# ESP32S31_RADIO register map
Vendor: Espressif; Series: ESP32-S31; File version: 3.52
Registers are 32-bit, read-write, no defined reset value unless marked. A register's access mark holds for its fields unless they carry their own. Offsets are from the block's base; [hi:lo] are bit positions; {n}, {i} and the like mark numbered series; 'fields as' and 'values as' point back to an identical list.

## MODEM_RADIO_CORE_LOW_OBSERVED — Sparse source-qualified word views in the existing owned MMIO aperture; individual meanings and side effects remain unknown.
Base 0x20100000
0x470 WORD_0470_OPAQUE ro — Opaque: meaning not established. Aligned 32-bit bus view explicitly addressed by the cited vendor source. No reset or hardware write effect is established.
  [31:0] BITS_0_31_OPAQUE — Opaque: meaning not established. Observed source use; the individual hardware meaning is unknown.
0x474 WORD_0474_OPAQUE ro — Opaque: meaning not established. Aligned 32-bit bus view explicitly addressed by the cited vendor source. No reset or hardware write effect is established.
  fields as WORD_0470_OPAQUE
0x1018 WORD_1018_OPAQUE ro — Opaque: meaning not established. Aligned 32-bit bus view explicitly addressed by the cited vendor source. No reset or hardware write effect is established.
  [0] BIT_0_OPAQUE — Opaque: meaning not established. Observed source use; the individual hardware meaning is unknown.
0x1038 WORD_1038_OPAQUE ro — Opaque: meaning not established. Aligned 32-bit bus view explicitly addressed by the cited vendor source. No reset or hardware write effect is established.
  fields as WORD_1018_OPAQUE
0x1048 WORD_1048_OPAQUE ro — Opaque: meaning not established. Aligned 32-bit bus view explicitly addressed by the cited vendor source. No reset or hardware write effect is established.
  fields as WORD_1018_OPAQUE
0x106C WORD_106C_OPAQUE — Opaque: meaning not established. Aligned 32-bit bus view explicitly addressed by the cited vendor source. No reset or hardware write effect is established.
  fields as WORD_0470_OPAQUE
0x1088 WORD_1088_OPAQUE — Opaque: meaning not established. Aligned 32-bit bus view explicitly addressed by the cited vendor source. No reset or hardware write effect is established.
  [7:0] BITS_0_7_OPAQUE — Opaque: meaning not established. Observed source use; the individual hardware meaning is unknown.
0x10D0 WORD_10D0_OPAQUE ro — Opaque: meaning not established. Aligned 32-bit bus view explicitly addressed by the cited vendor source. No reset or hardware write effect is established.
  [20:0] BITS_0_20_OPAQUE — Opaque: meaning not established. Observed source use; the individual hardware meaning is unknown.
0x10D4 WORD_10D4_OPAQUE ro — Opaque: meaning not established. Aligned 32-bit bus view explicitly addressed by the cited vendor source. No reset or hardware write effect is established.
  fields as WORD_10D0_OPAQUE
0x122C WORD_122C_OPAQUE ro — Opaque: meaning not established. Aligned 32-bit bus view explicitly addressed by the cited vendor source. No reset or hardware write effect is established.
  fields as WORD_0470_OPAQUE
0x1230 WORD_1230_OPAQUE ro — Opaque: meaning not established. Aligned 32-bit bus view explicitly addressed by the cited vendor source. No reset or hardware write effect is established.
  [19:0] BITS_0_19_OPAQUE — Opaque: meaning not established. Observed source use; the individual hardware meaning is unknown.
0x126C WORD_126C_OPAQUE ro — Opaque: meaning not established. Aligned 32-bit bus view explicitly addressed by the cited vendor source. No reset or hardware write effect is established.
  fields as WORD_0470_OPAQUE
0x1270 WORD_1270_OPAQUE ro — Opaque: meaning not established. Aligned 32-bit bus view explicitly addressed by the cited vendor source. No reset or hardware write effect is established.
  fields as WORD_0470_OPAQUE
0x1274 WORD_1274_OPAQUE ro — Opaque: meaning not established. Aligned 32-bit bus view explicitly addressed by the cited vendor source. No reset or hardware write effect is established.
  fields as WORD_0470_OPAQUE
0x1278 WORD_1278_OPAQUE ro — Opaque: meaning not established. Aligned 32-bit bus view explicitly addressed by the cited vendor source. No reset or hardware write effect is established.
  fields as WORD_0470_OPAQUE
0x1298 WORD_1298_OPAQUE ro — Opaque: meaning not established. Aligned 32-bit bus view explicitly addressed by the cited vendor source. No reset or hardware write effect is established.
  fields as WORD_0470_OPAQUE
0x12AC WORD_12AC_OPAQUE ro — Opaque: meaning not established. Aligned 32-bit bus view explicitly addressed by the cited vendor source. No reset or hardware write effect is established.
  fields as WORD_0470_OPAQUE
0x12B0 WORD_12B0_OPAQUE ro — Opaque: meaning not established. Aligned 32-bit bus view explicitly addressed by the cited vendor source. No reset or hardware write effect is established.
  fields as WORD_0470_OPAQUE
0x12B4 WORD_12B4_OPAQUE ro — Opaque: meaning not established. Aligned 32-bit bus view explicitly addressed by the cited vendor source. No reset or hardware write effect is established.
  fields as WORD_0470_OPAQUE
0x12B8 WORD_12B8_OPAQUE ro — Opaque: meaning not established. Aligned 32-bit bus view explicitly addressed by the cited vendor source. No reset or hardware write effect is established.
  fields as WORD_0470_OPAQUE
0x12BC WORD_12BC_OPAQUE ro — Opaque: meaning not established. Aligned 32-bit bus view explicitly addressed by the cited vendor source. No reset or hardware write effect is established.
  fields as WORD_0470_OPAQUE
0x12C0 WORD_12C0_OPAQUE ro — Opaque: meaning not established. Aligned 32-bit bus view explicitly addressed by the cited vendor source. No reset or hardware write effect is established.
  fields as WORD_0470_OPAQUE
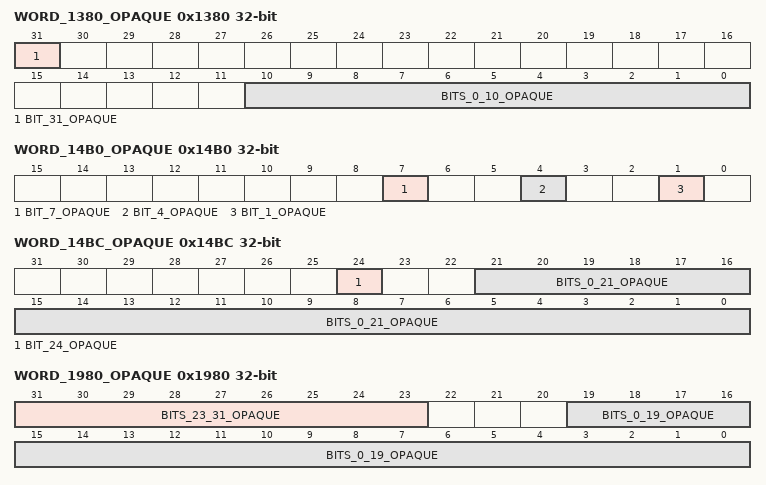
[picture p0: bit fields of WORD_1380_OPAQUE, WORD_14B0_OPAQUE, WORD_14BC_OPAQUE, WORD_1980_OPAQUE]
0x1380 WORD_1380_OPAQUE — Opaque: meaning not established. Aligned 32-bit bus view explicitly addressed by the cited vendor source. No reset or hardware write effect is established.
  [31] BIT_31_OPAQUE — Opaque: meaning not established. Observed source use; the individual hardware meaning is unknown.
  [10:0] BITS_0_10_OPAQUE — Opaque: meaning not established. Observed source use; the individual hardware meaning is unknown.
0x13D8 WORD_13D8_OPAQUE — Opaque: meaning not established. Aligned 32-bit bus view explicitly addressed by the cited vendor source. No reset or hardware write effect is established.
  fields as WORD_0470_OPAQUE
0x13DC WORD_13DC_OPAQUE — Opaque: meaning not established. Aligned 32-bit bus view explicitly addressed by the cited vendor source. No reset or hardware write effect is established.
  fields as WORD_0470_OPAQUE
0x13E0 WORD_13E0_OPAQUE — Opaque: meaning not established. Aligned 32-bit bus view explicitly addressed by the cited vendor source. No reset or hardware write effect is established.
  fields as WORD_0470_OPAQUE
0x13E4 WORD_13E4_OPAQUE — Opaque: meaning not established. Aligned 32-bit bus view explicitly addressed by the cited vendor source. No reset or hardware write effect is established.
  fields as WORD_0470_OPAQUE
0x13F4 WORD_13F4_OPAQUE — Opaque: meaning not established. Aligned 32-bit bus view explicitly addressed by the cited vendor source. No reset or hardware write effect is established.
  [1] BIT_1_OPAQUE — Opaque: meaning not established. Observed source use; the individual hardware meaning is unknown.
0x13FC WORD_13FC_OPAQUE — Opaque: meaning not established. Aligned 32-bit bus view explicitly addressed by the cited vendor source. No reset or hardware write effect is established.
  [27:0] BITS_0_27_OPAQUE — Opaque: meaning not established. Observed source use; the individual hardware meaning is unknown.
0x1430 WORD_1430_OPAQUE — Opaque: meaning not established. Aligned 32-bit bus view explicitly addressed by the cited vendor source. No reset or hardware write effect is established.
  fields as WORD_0470_OPAQUE
0x1434 WORD_1434_OPAQUE — Opaque: meaning not established. Aligned 32-bit bus view explicitly addressed by the cited vendor source. No reset or hardware write effect is established.
  fields as WORD_0470_OPAQUE
0x1438 WORD_1438_OPAQUE — Opaque: meaning not established. Aligned 32-bit bus view explicitly addressed by the cited vendor source. No reset or hardware write effect is established.
  fields as WORD_0470_OPAQUE
0x143C WORD_143C_OPAQUE — Opaque: meaning not established. Aligned 32-bit bus view explicitly addressed by the cited vendor source. No reset or hardware write effect is established.
  fields as WORD_0470_OPAQUE
0x1450 WORD_1450_OPAQUE — Opaque: meaning not established. Aligned 32-bit bus view explicitly addressed by the cited vendor source. No reset or hardware write effect is established.
  fields as WORD_0470_OPAQUE
0x145C WORD_145C_OPAQUE — Opaque: meaning not established. Aligned 32-bit bus view explicitly addressed by the cited vendor source. No reset or hardware write effect is established.
  fields as WORD_0470_OPAQUE
0x1470 WORD_1470_OPAQUE — Opaque: meaning not established. Aligned 32-bit bus view explicitly addressed by the cited vendor source. No reset or hardware write effect is established.
  fields as WORD_0470_OPAQUE
0x147C WORD_147C_OPAQUE ro — Opaque: meaning not established. Aligned 32-bit bus view explicitly addressed by the cited vendor source. No reset or hardware write effect is established.
  fields as WORD_1018_OPAQUE
0x14B0 WORD_14B0_OPAQUE — Opaque: meaning not established. Aligned 32-bit bus view explicitly addressed by the cited vendor source. No reset or hardware write effect is established.
  [7] BIT_7_OPAQUE — Opaque: meaning not established. Observed source use; the individual hardware meaning is unknown.
  [4] BIT_4_OPAQUE — Opaque: meaning not established. Observed source use; the individual hardware meaning is unknown.
  [1] BIT_1_OPAQUE — Opaque: meaning not established. Observed source use; the individual hardware meaning is unknown.
0x14BC WORD_14BC_OPAQUE ro — Opaque: meaning not established. Aligned 32-bit bus view explicitly addressed by the cited vendor source. No reset or hardware write effect is established.
  [24] BIT_24_OPAQUE — Opaque: meaning not established. Observed source use; the individual hardware meaning is unknown.
  [21:0] BITS_0_21_OPAQUE — Opaque: meaning not established. Observed source use; the individual hardware meaning is unknown.
0x14C4 WORD_14C4_OPAQUE — Opaque: meaning not established. Aligned 32-bit bus view explicitly addressed by the cited vendor source. No reset or hardware write effect is established.
  [10] BIT_10_OPAQUE — Opaque: meaning not established. Observed source use; the individual hardware meaning is unknown.
0x14C8 WORD_14C8_OPAQUE — Opaque: meaning not established. Aligned 32-bit bus view explicitly addressed by the cited vendor source. No reset or hardware write effect is established.
  fields as WORD_14C4_OPAQUE
0x14CC WORD_14CC_OPAQUE ro — Opaque: meaning not established. Aligned 32-bit bus view explicitly addressed by the cited vendor source. No reset or hardware write effect is established.
  [10:9] BITS_9_10_OPAQUE — Opaque: meaning not established. Observed source use; the individual hardware meaning is unknown.
0x1508 WORD_1508_OPAQUE — Opaque: meaning not established. Aligned 32-bit bus view explicitly addressed by the cited vendor source. No reset or hardware write effect is established.
  [6:0] BITS_0_6_OPAQUE — Opaque: meaning not established. Observed source use; the individual hardware meaning is unknown.
0x1510 WORD_1510_OPAQUE — Opaque: meaning not established. Aligned 32-bit bus view explicitly addressed by the cited vendor source. No reset or hardware write effect is established.
  fields as WORD_0470_OPAQUE
0x1514 WORD_1514_OPAQUE — Opaque: meaning not established. Aligned 32-bit bus view explicitly addressed by the cited vendor source. No reset or hardware write effect is established.
  fields as WORD_0470_OPAQUE
0x1518 WORD_1518_OPAQUE — Opaque: meaning not established. Aligned 32-bit bus view explicitly addressed by the cited vendor source. No reset or hardware write effect is established.
  fields as WORD_0470_OPAQUE
0x1524 WORD_1524_OPAQUE — Opaque: meaning not established. Aligned 32-bit bus view explicitly addressed by the cited vendor source. No reset or hardware write effect is established.
  fields as WORD_0470_OPAQUE
0x1528 WORD_1528_OPAQUE — Opaque: meaning not established. Aligned 32-bit bus view explicitly addressed by the cited vendor source. No reset or hardware write effect is established.
  fields as WORD_0470_OPAQUE
0x1548 WORD_1548_OPAQUE ro — Opaque: meaning not established. Aligned 32-bit bus view explicitly addressed by the cited vendor source. No reset or hardware write effect is established.
  fields as WORD_1088_OPAQUE
0x1980 WORD_1980_OPAQUE — Opaque: meaning not established. Aligned 32-bit bus view explicitly addressed by the cited vendor source. No reset or hardware write effect is established.
  [31:23] BITS_23_31_OPAQUE — Opaque: meaning not established. Observed source use; the individual hardware meaning is unknown.
  [19:0] BITS_0_19_OPAQUE — Opaque: meaning not established. Observed source use; the individual hardware meaning is unknown.
0x198C WORD_198C_OPAQUE — Opaque: meaning not established. Aligned 32-bit bus view explicitly addressed by the cited vendor source. No reset or hardware write effect is established.
  fields as WORD_0470_OPAQUE
0x1994 WORD_1994_OPAQUE — Opaque: meaning not established. Aligned 32-bit bus view explicitly addressed by the cited vendor source. No reset or hardware write effect is established.
  fields as WORD_0470_OPAQUE
0x1FFC WORD_1FFC_OPAQUE — Opaque: meaning not established. Aligned 32-bit bus view explicitly addressed by the cited vendor source. No reset or hardware write effect is established.
  fields as WORD_0470_OPAQUE
0x2018 WORD_2018_OPAQUE — Opaque: meaning not established. Aligned 32-bit bus view explicitly addressed by the cited vendor source. No reset or hardware write effect is established.
  [26:16] BITS_16_26_OPAQUE — Opaque: meaning not established. Observed source use; the individual hardware meaning is unknown.
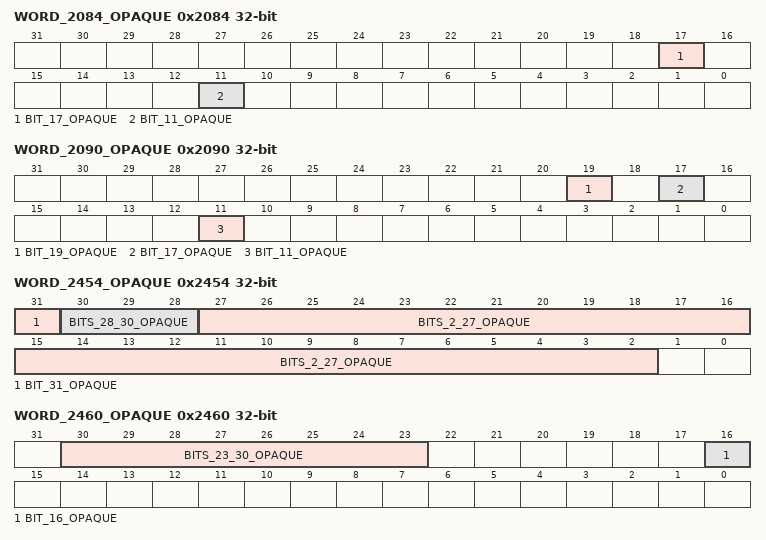
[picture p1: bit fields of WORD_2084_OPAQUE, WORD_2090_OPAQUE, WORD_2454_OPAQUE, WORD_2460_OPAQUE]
0x2084 WORD_2084_OPAQUE — Opaque: meaning not established. Aligned 32-bit bus view explicitly addressed by the cited vendor source. No reset or hardware write effect is established.
  [17] BIT_17_OPAQUE — Opaque: meaning not established. Observed source use; the individual hardware meaning is unknown.
  [11] BIT_11_OPAQUE — Opaque: meaning not established. Observed source use; the individual hardware meaning is unknown.
0x2088 WORD_2088_OPAQUE ro — Opaque: meaning not established. Aligned 32-bit bus view explicitly addressed by the cited vendor source. No reset or hardware write effect is established.
  fields as WORD_1230_OPAQUE
0x2090 WORD_2090_OPAQUE — Opaque: meaning not established. Aligned 32-bit bus view explicitly addressed by the cited vendor source. No reset or hardware write effect is established.
  [19] BIT_19_OPAQUE — Opaque: meaning not established. Observed source use; the individual hardware meaning is unknown.
  [17] BIT_17_OPAQUE — Opaque: meaning not established. Observed source use; the individual hardware meaning is unknown.
  [11] BIT_11_OPAQUE — Opaque: meaning not established. Observed source use; the individual hardware meaning is unknown.
0x20AC WORD_20AC_OPAQUE — Opaque: meaning not established. Aligned 32-bit bus view explicitly addressed by the cited vendor source. No reset or hardware write effect is established.
  [31:29] BITS_29_31_OPAQUE — Opaque: meaning not established. Observed source use; the individual hardware meaning is unknown.
0x21B0 WORD_21B0_OPAQUE — Opaque: meaning not established. Aligned 32-bit bus view explicitly addressed by the cited vendor source. No reset or hardware write effect is established.
  fields as WORD_0470_OPAQUE
0x2454 WORD_2454_OPAQUE — Opaque: meaning not established. Aligned 32-bit bus view explicitly addressed by the cited vendor source. No reset or hardware write effect is established.
  [31] BIT_31_OPAQUE — Opaque: meaning not established. Observed source use; the individual hardware meaning is unknown.
  [30:28] BITS_28_30_OPAQUE — Opaque: meaning not established. Observed source use; the individual hardware meaning is unknown.
  [27:2] BITS_2_27_OPAQUE — Opaque: meaning not established. Observed source use; the individual hardware meaning is unknown.
0x2458 WORD_2458_OPAQUE — Opaque: meaning not established. Aligned 32-bit bus view explicitly addressed by the cited vendor source. No reset or hardware write effect is established.
  fields as WORD_0470_OPAQUE
0x2460 WORD_2460_OPAQUE — Opaque: meaning not established. Aligned 32-bit bus view explicitly addressed by the cited vendor source. No reset or hardware write effect is established.
  [30:23] BITS_23_30_OPAQUE — Opaque: meaning not established. Observed source use; the individual hardware meaning is unknown.
  [16] BIT_16_OPAQUE — Opaque: meaning not established. Observed source use; the individual hardware meaning is unknown.
0x2464 WORD_2464_OPAQUE ro — Opaque: meaning not established. Aligned 32-bit bus view explicitly addressed by the cited vendor source. No reset or hardware write effect is established.
  fields as WORD_0470_OPAQUE
0x4090 WORD_4090_OPAQUE ro — Opaque: meaning not established. Aligned 32-bit bus view explicitly addressed by the cited vendor source. No reset or hardware write effect is established.
  fields as WORD_0470_OPAQUE
0x4094 WORD_4094_OPAQUE ro — Opaque: meaning not established. Aligned 32-bit bus view explicitly addressed by the cited vendor source. No reset or hardware write effect is established.
  fields as WORD_0470_OPAQUE
0x40A4 WORD_40A4_OPAQUE — Opaque: meaning not established. Aligned 32-bit bus view explicitly addressed by the cited vendor source. No reset or hardware write effect is established.
  [15:12] BITS_12_15_OPAQUE — Opaque: meaning not established. Observed source use; the individual hardware meaning is unknown.
0x40AC WORD_40AC_OPAQUE ro — Opaque: meaning not established. Aligned 32-bit bus view explicitly addressed by the cited vendor source. No reset or hardware write effect is established.
  fields as WORD_0470_OPAQUE
0x43A8 WORD_43A8_OPAQUE ro — Opaque: meaning not established. Aligned 32-bit bus view explicitly addressed by the cited vendor source. No reset or hardware write effect is established.
  fields as WORD_0470_OPAQUE
0x4494 WORD_4494_OPAQUE — Opaque: meaning not established. Aligned 32-bit bus view explicitly addressed by the cited vendor source. No reset or hardware write effect is established.
  [15] BIT_15_OPAQUE — Opaque: meaning not established. Observed source use; the individual hardware meaning is unknown.
0x44C4 WORD_44C4_OPAQUE — Opaque: meaning not established. Aligned 32-bit bus view explicitly addressed by the cited vendor source. No reset or hardware write effect is established.
  [29:0] BITS_0_29_OPAQUE — Opaque: meaning not established. Observed source use; the individual hardware meaning is unknown.
0x44C8 WORD_44C8_OPAQUE — Opaque: meaning not established. Aligned 32-bit bus view explicitly addressed by the cited vendor source. No reset or hardware write effect is established.
  fields as WORD_13FC_OPAQUE
0x44CC WORD_44CC_OPAQUE — Opaque: meaning not established. Aligned 32-bit bus view explicitly addressed by the cited vendor source. No reset or hardware write effect is established.
  fields as WORD_0470_OPAQUE
0x44D0 WORD_44D0_OPAQUE — Opaque: meaning not established. Aligned 32-bit bus view explicitly addressed by the cited vendor source. No reset or hardware write effect is established.
  [30:0] BITS_0_30_OPAQUE — Opaque: meaning not established. Observed source use; the individual hardware meaning is unknown.
0x44D4 WORD_44D4_OPAQUE — Opaque: meaning not established. Aligned 32-bit bus view explicitly addressed by the cited vendor source. No reset or hardware write effect is established.
  fields as WORD_0470_OPAQUE
0x4C50 WORD_4C50_OPAQUE — Opaque: meaning not established. Aligned 32-bit bus view explicitly addressed by the cited vendor source. No reset or hardware write effect is established.
  [15:0] BITS_0_15_OPAQUE — Opaque: meaning not established. Observed source use; the individual hardware meaning is unknown.
0x4C74 WORD_4C74_OPAQUE ro — Opaque: meaning not established. Aligned 32-bit bus view explicitly addressed by the cited vendor source. No reset or hardware write effect is established.
  [31:28] BITS_28_31_OPAQUE — Opaque: meaning not established. Observed source use; the individual hardware meaning is unknown.
0x4C94 WORD_4C94_OPAQUE — Opaque: meaning not established. Aligned source-qualified 32-bit bus view in the existing owned aperture. No reset, safe transaction or read safety is established.
  fields as WORD_1088_OPAQUE
0x4CFC WORD_4CFC_OPAQUE ro — Opaque: meaning not established. Aligned 32-bit bus view explicitly addressed by the cited vendor source. No reset or hardware write effect is established.
  fields as WORD_0470_OPAQUE
{0x4D0C+0x10*i} WORD_4D{i}C_OPAQUE ro (i=0..2) — Opaque: meaning not established. Aligned 32-bit bus view explicitly addressed by the cited vendor source. No reset or hardware write effect is established.
  fields as WORD_0470_OPAQUE
0x4E3C WORD_4E3C_OPAQUE — Opaque: meaning not established. Aligned 32-bit bus view explicitly addressed by the cited vendor source. No reset or hardware write effect is established.
  [8:0] BITS_0_8_OPAQUE — Opaque: meaning not established. Observed source use; the individual hardware meaning is unknown.
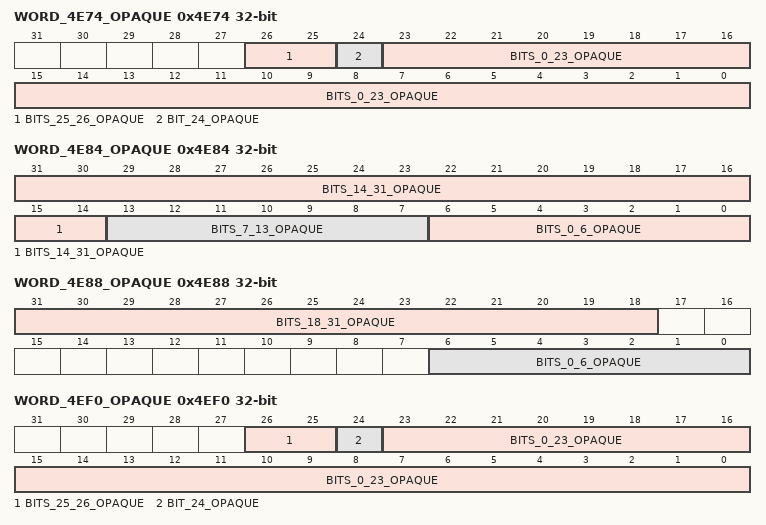
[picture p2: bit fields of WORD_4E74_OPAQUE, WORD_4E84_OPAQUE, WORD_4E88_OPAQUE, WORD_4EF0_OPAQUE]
0x4E74 WORD_4E74_OPAQUE ro — Opaque: meaning not established. Aligned 32-bit bus view explicitly addressed by the cited vendor source. No reset or hardware write effect is established.
  [26:25] BITS_25_26_OPAQUE — Opaque: meaning not established. Observed source use; the individual hardware meaning is unknown.
  [24] BIT_24_OPAQUE — Opaque: meaning not established. Observed source use; the individual hardware meaning is unknown.
  [23:0] BITS_0_23_OPAQUE — Opaque: meaning not established. Observed source use; the individual hardware meaning is unknown.
0x4E7C WORD_4E7C_OPAQUE ro — Opaque: meaning not established. Aligned 32-bit bus view explicitly addressed by the cited vendor source. No reset or hardware write effect is established.
  [18:0] BITS_0_18_OPAQUE — Opaque: meaning not established. Observed source use; the individual hardware meaning is unknown.
0x4E80 WORD_4E80_OPAQUE ro — Opaque: meaning not established. Aligned 32-bit bus view explicitly addressed by the cited vendor source. No reset or hardware write effect is established.
  fields as WORD_0470_OPAQUE
0x4E84 WORD_4E84_OPAQUE ro — Opaque: meaning not established. Aligned 32-bit bus view explicitly addressed by the cited vendor source. No reset or hardware write effect is established.
  [31:14] BITS_14_31_OPAQUE — Opaque: meaning not established. Observed source use; the individual hardware meaning is unknown.
  [13:7] BITS_7_13_OPAQUE — Opaque: meaning not established. Observed source use; the individual hardware meaning is unknown.
  [6:0] BITS_0_6_OPAQUE — Opaque: meaning not established. Observed source use; the individual hardware meaning is unknown.
0x4E88 WORD_4E88_OPAQUE ro — Opaque: meaning not established. Aligned 32-bit bus view explicitly addressed by the cited vendor source. No reset or hardware write effect is established.
  [31:18] BITS_18_31_OPAQUE — Opaque: meaning not established. Observed source use; the individual hardware meaning is unknown.
  [6:0] BITS_0_6_OPAQUE — Opaque: meaning not established. Observed source use; the individual hardware meaning is unknown.
0x4EF0 WORD_4EF0_OPAQUE ro — Opaque: meaning not established. Aligned 32-bit bus view explicitly addressed by the cited vendor source. No reset or hardware write effect is established.
  fields as WORD_4E74_OPAQUE
0x4EF8 WORD_4EF8_OPAQUE ro — Opaque: meaning not established. Aligned 32-bit bus view explicitly addressed by the cited vendor source. No reset or hardware write effect is established.
  fields as WORD_4E7C_OPAQUE
0x4EFC WORD_4EFC_OPAQUE ro — Opaque: meaning not established. Aligned 32-bit bus view explicitly addressed by the cited vendor source. No reset or hardware write effect is established.
  fields as WORD_0470_OPAQUE
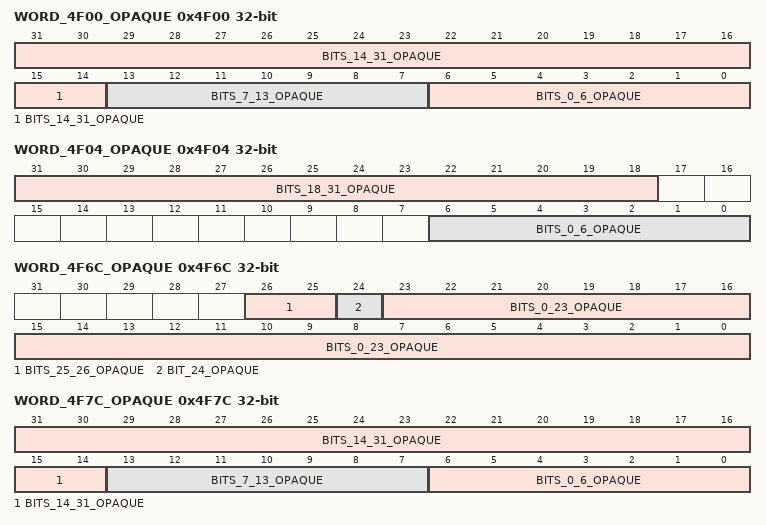
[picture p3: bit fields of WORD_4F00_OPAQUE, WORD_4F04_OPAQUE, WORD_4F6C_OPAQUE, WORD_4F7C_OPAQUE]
0x4F00 WORD_4F00_OPAQUE ro — Opaque: meaning not established. Aligned 32-bit bus view explicitly addressed by the cited vendor source. No reset or hardware write effect is established.
  fields as WORD_4E84_OPAQUE
0x4F04 WORD_4F04_OPAQUE ro — Opaque: meaning not established. Aligned 32-bit bus view explicitly addressed by the cited vendor source. No reset or hardware write effect is established.
  fields as WORD_4E88_OPAQUE
0x4F6C WORD_4F6C_OPAQUE ro — Opaque: meaning not established. Aligned 32-bit bus view explicitly addressed by the cited vendor source. No reset or hardware write effect is established.
  fields as WORD_4E74_OPAQUE
0x4F74 WORD_4F74_OPAQUE ro — Opaque: meaning not established. Aligned 32-bit bus view explicitly addressed by the cited vendor source. No reset or hardware write effect is established.
  fields as WORD_4E7C_OPAQUE
0x4F78 WORD_4F78_OPAQUE ro — Opaque: meaning not established. Aligned 32-bit bus view explicitly addressed by the cited vendor source. No reset or hardware write effect is established.
  fields as WORD_0470_OPAQUE
0x4F7C WORD_4F7C_OPAQUE ro — Opaque: meaning not established. Aligned 32-bit bus view explicitly addressed by the cited vendor source. No reset or hardware write effect is established.
  fields as WORD_4E84_OPAQUE
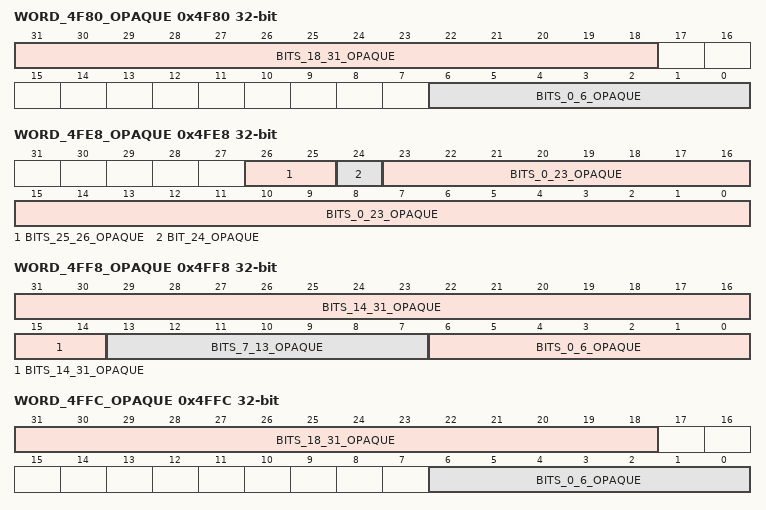
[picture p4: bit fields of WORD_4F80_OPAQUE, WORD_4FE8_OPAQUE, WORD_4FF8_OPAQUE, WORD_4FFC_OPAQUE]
0x4F80 WORD_4F80_OPAQUE ro — Opaque: meaning not established. Aligned 32-bit bus view explicitly addressed by the cited vendor source. No reset or hardware write effect is established.
  fields as WORD_4E88_OPAQUE
0x4FE8 WORD_4FE8_OPAQUE ro — Opaque: meaning not established. Aligned 32-bit bus view explicitly addressed by the cited vendor source. No reset or hardware write effect is established.
  fields as WORD_4E74_OPAQUE
0x4FF0 WORD_4FF0_OPAQUE ro — Opaque: meaning not established. Aligned 32-bit bus view explicitly addressed by the cited vendor source. No reset or hardware write effect is established.
  fields as WORD_4E7C_OPAQUE
0x4FF4 WORD_4FF4_OPAQUE ro — Opaque: meaning not established. Aligned 32-bit bus view explicitly addressed by the cited vendor source. No reset or hardware write effect is established.
  fields as WORD_0470_OPAQUE
0x4FF8 WORD_4FF8_OPAQUE ro — Opaque: meaning not established. Aligned 32-bit bus view explicitly addressed by the cited vendor source. No reset or hardware write effect is established.
  fields as WORD_4E84_OPAQUE
0x4FFC WORD_4FFC_OPAQUE ro — Opaque: meaning not established. Aligned 32-bit bus view explicitly addressed by the cited vendor source. No reset or hardware write effect is established.
  fields as WORD_4E88_OPAQUE
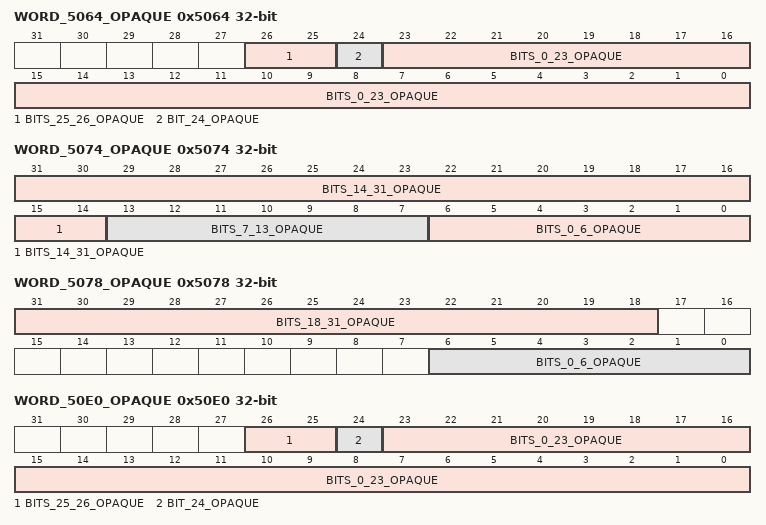
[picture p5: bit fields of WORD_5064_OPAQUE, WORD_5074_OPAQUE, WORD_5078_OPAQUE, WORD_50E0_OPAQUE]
0x5064 WORD_5064_OPAQUE ro — Opaque: meaning not established. Aligned 32-bit bus view explicitly addressed by the cited vendor source. No reset or hardware write effect is established.
  fields as WORD_4E74_OPAQUE
0x506C WORD_506C_OPAQUE ro — Opaque: meaning not established. Aligned 32-bit bus view explicitly addressed by the cited vendor source. No reset or hardware write effect is established.
  fields as WORD_4E7C_OPAQUE
0x5070 WORD_5070_OPAQUE ro — Opaque: meaning not established. Aligned 32-bit bus view explicitly addressed by the cited vendor source. No reset or hardware write effect is established.
  fields as WORD_0470_OPAQUE
0x5074 WORD_5074_OPAQUE ro — Opaque: meaning not established. Aligned 32-bit bus view explicitly addressed by the cited vendor source. No reset or hardware write effect is established.
  fields as WORD_4E84_OPAQUE
0x5078 WORD_5078_OPAQUE ro — Opaque: meaning not established. Aligned 32-bit bus view explicitly addressed by the cited vendor source. No reset or hardware write effect is established.
  fields as WORD_4E88_OPAQUE
0x50E0 WORD_50E0_OPAQUE ro — Opaque: meaning not established. Aligned 32-bit bus view explicitly addressed by the cited vendor source. No reset or hardware write effect is established.
  fields as WORD_4E74_OPAQUE
0x50E8 WORD_50E8_OPAQUE ro — Opaque: meaning not established. Aligned 32-bit bus view explicitly addressed by the cited vendor source. No reset or hardware write effect is established.
  fields as WORD_4E7C_OPAQUE
0x50EC WORD_50EC_OPAQUE ro — Opaque: meaning not established. Aligned 32-bit bus view explicitly addressed by the cited vendor source. No reset or hardware write effect is established.
  fields as WORD_0470_OPAQUE
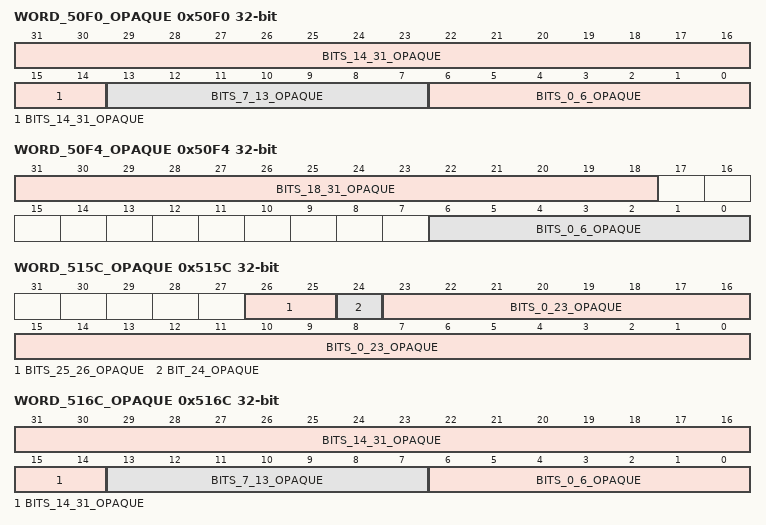
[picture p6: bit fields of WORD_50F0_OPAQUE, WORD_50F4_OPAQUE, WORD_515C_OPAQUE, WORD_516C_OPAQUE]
0x50F0 WORD_50F0_OPAQUE ro — Opaque: meaning not established. Aligned 32-bit bus view explicitly addressed by the cited vendor source. No reset or hardware write effect is established.
  fields as WORD_4E84_OPAQUE
0x50F4 WORD_50F4_OPAQUE ro — Opaque: meaning not established. Aligned 32-bit bus view explicitly addressed by the cited vendor source. No reset or hardware write effect is established.
  fields as WORD_4E88_OPAQUE
0x515C WORD_515C_OPAQUE ro — Opaque: meaning not established. Aligned 32-bit bus view explicitly addressed by the cited vendor source. No reset or hardware write effect is established.
  fields as WORD_4E74_OPAQUE
0x5164 WORD_5164_OPAQUE ro — Opaque: meaning not established. Aligned 32-bit bus view explicitly addressed by the cited vendor source. No reset or hardware write effect is established.
  fields as WORD_4E7C_OPAQUE
0x5168 WORD_5168_OPAQUE ro — Opaque: meaning not established. Aligned 32-bit bus view explicitly addressed by the cited vendor source. No reset or hardware write effect is established.
  fields as WORD_0470_OPAQUE
0x516C WORD_516C_OPAQUE ro — Opaque: meaning not established. Aligned 32-bit bus view explicitly addressed by the cited vendor source. No reset or hardware write effect is established.
  fields as WORD_4E84_OPAQUE
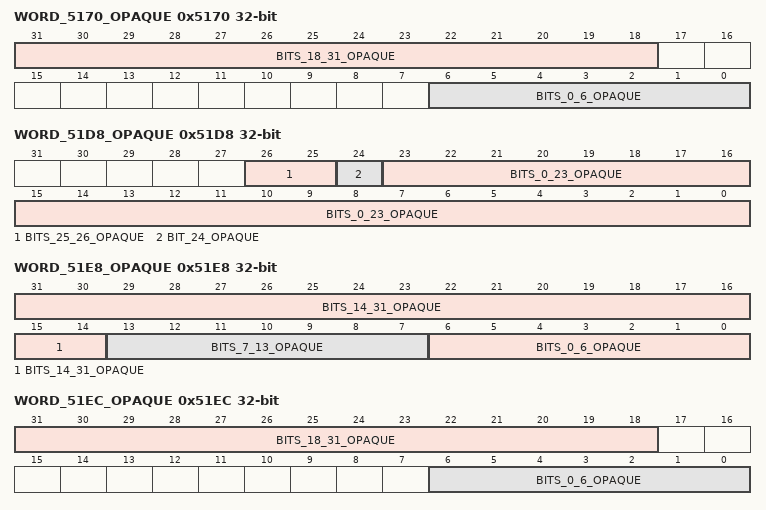
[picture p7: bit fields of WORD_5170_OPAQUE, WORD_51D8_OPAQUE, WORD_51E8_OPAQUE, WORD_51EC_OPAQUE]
0x5170 WORD_5170_OPAQUE ro — Opaque: meaning not established. Aligned 32-bit bus view explicitly addressed by the cited vendor source. No reset or hardware write effect is established.
  fields as WORD_4E88_OPAQUE
0x51D8 WORD_51D8_OPAQUE ro — Opaque: meaning not established. Aligned 32-bit bus view explicitly addressed by the cited vendor source. No reset or hardware write effect is established.
  fields as WORD_4E74_OPAQUE
0x51E0 WORD_51E0_OPAQUE ro — Opaque: meaning not established. Aligned 32-bit bus view explicitly addressed by the cited vendor source. No reset or hardware write effect is established.
  fields as WORD_4E7C_OPAQUE
0x51E4 WORD_51E4_OPAQUE ro — Opaque: meaning not established. Aligned 32-bit bus view explicitly addressed by the cited vendor source. No reset or hardware write effect is established.
  fields as WORD_0470_OPAQUE
0x51E8 WORD_51E8_OPAQUE ro — Opaque: meaning not established. Aligned 32-bit bus view explicitly addressed by the cited vendor source. No reset or hardware write effect is established.
  fields as WORD_4E84_OPAQUE
0x51EC WORD_51EC_OPAQUE ro — Opaque: meaning not established. Aligned 32-bit bus view explicitly addressed by the cited vendor source. No reset or hardware write effect is established.
  fields as WORD_4E88_OPAQUE
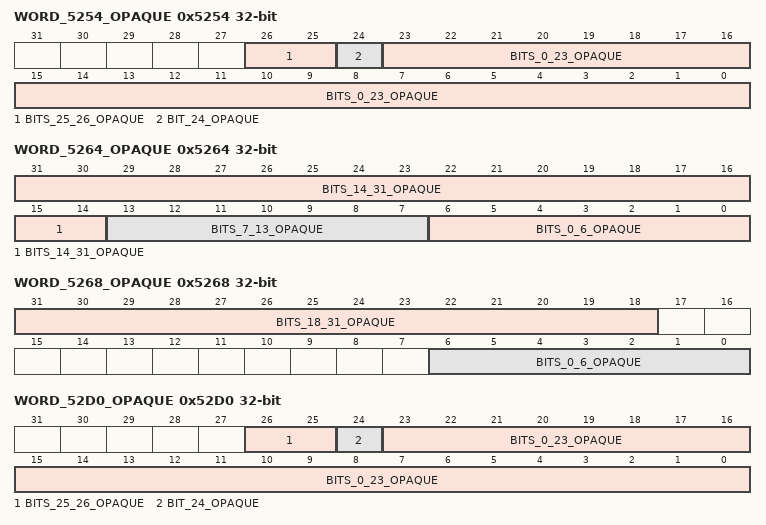
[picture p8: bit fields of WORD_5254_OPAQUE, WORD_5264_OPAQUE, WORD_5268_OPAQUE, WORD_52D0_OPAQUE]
0x5254 WORD_5254_OPAQUE ro — Opaque: meaning not established. Aligned 32-bit bus view explicitly addressed by the cited vendor source. No reset or hardware write effect is established.
  fields as WORD_4E74_OPAQUE
0x525C WORD_525C_OPAQUE ro — Opaque: meaning not established. Aligned 32-bit bus view explicitly addressed by the cited vendor source. No reset or hardware write effect is established.
  fields as WORD_4E7C_OPAQUE
0x5260 WORD_5260_OPAQUE ro — Opaque: meaning not established. Aligned 32-bit bus view explicitly addressed by the cited vendor source. No reset or hardware write effect is established.
  fields as WORD_0470_OPAQUE
0x5264 WORD_5264_OPAQUE ro — Opaque: meaning not established. Aligned 32-bit bus view explicitly addressed by the cited vendor source. No reset or hardware write effect is established.
  fields as WORD_4E84_OPAQUE
0x5268 WORD_5268_OPAQUE ro — Opaque: meaning not established. Aligned 32-bit bus view explicitly addressed by the cited vendor source. No reset or hardware write effect is established.
  fields as WORD_4E88_OPAQUE
0x52D0 WORD_52D0_OPAQUE ro — Opaque: meaning not established. Aligned 32-bit bus view explicitly addressed by the cited vendor source. No reset or hardware write effect is established.
  fields as WORD_4E74_OPAQUE
0x52D8 WORD_52D8_OPAQUE ro — Opaque: meaning not established. Aligned 32-bit bus view explicitly addressed by the cited vendor source. No reset or hardware write effect is established.
  fields as WORD_4E7C_OPAQUE
0x52DC WORD_52DC_OPAQUE ro — Opaque: meaning not established. Aligned 32-bit bus view explicitly addressed by the cited vendor source. No reset or hardware write effect is established.
  fields as WORD_0470_OPAQUE
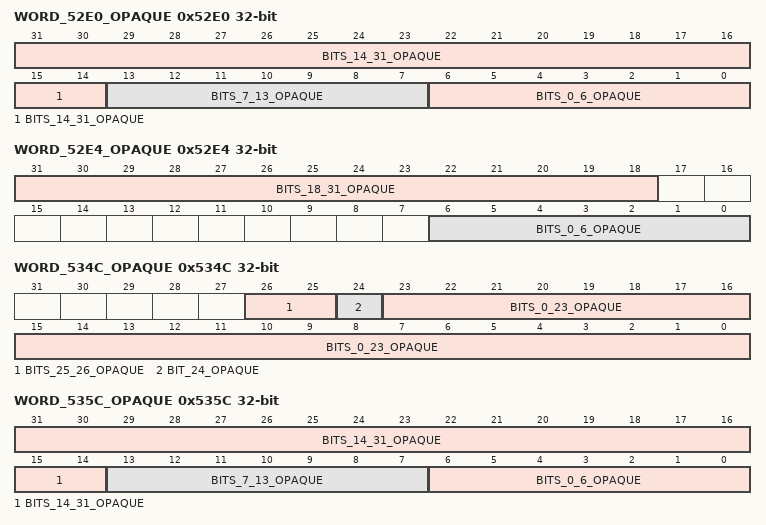
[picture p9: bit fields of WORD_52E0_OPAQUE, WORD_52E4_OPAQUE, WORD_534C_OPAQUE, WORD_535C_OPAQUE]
0x52E0 WORD_52E0_OPAQUE ro — Opaque: meaning not established. Aligned 32-bit bus view explicitly addressed by the cited vendor source. No reset or hardware write effect is established.
  fields as WORD_4E84_OPAQUE
0x52E4 WORD_52E4_OPAQUE ro — Opaque: meaning not established. Aligned 32-bit bus view explicitly addressed by the cited vendor source. No reset or hardware write effect is established.
  fields as WORD_4E88_OPAQUE
0x534C WORD_534C_OPAQUE ro — Opaque: meaning not established. Aligned 32-bit bus view explicitly addressed by the cited vendor source. No reset or hardware write effect is established.
  fields as WORD_4E74_OPAQUE
0x5354 WORD_5354_OPAQUE ro — Opaque: meaning not established. Aligned 32-bit bus view explicitly addressed by the cited vendor source. No reset or hardware write effect is established.
  fields as WORD_4E7C_OPAQUE
0x5358 WORD_5358_OPAQUE ro — Opaque: meaning not established. Aligned 32-bit bus view explicitly addressed by the cited vendor source. No reset or hardware write effect is established.
  fields as WORD_0470_OPAQUE
0x535C WORD_535C_OPAQUE ro — Opaque: meaning not established. Aligned 32-bit bus view explicitly addressed by the cited vendor source. No reset or hardware write effect is established.
  fields as WORD_4E84_OPAQUE
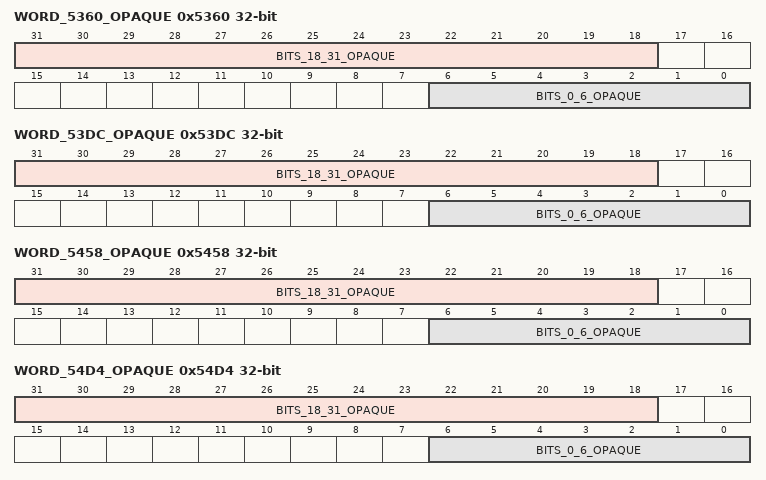
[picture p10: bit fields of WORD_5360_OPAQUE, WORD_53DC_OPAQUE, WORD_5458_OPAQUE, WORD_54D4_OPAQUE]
0x5360 WORD_5360_OPAQUE ro — Opaque: meaning not established. Aligned 32-bit bus view explicitly addressed by the cited vendor source. No reset or hardware write effect is established.
  fields as WORD_4E88_OPAQUE
0x53D0 WORD_53D0_OPAQUE ro — Opaque: meaning not established. Aligned 32-bit bus view explicitly addressed by the cited vendor source. No reset or hardware write effect is established.
  fields as WORD_4E7C_OPAQUE
0x53D4 WORD_53D4_OPAQUE ro — Opaque: meaning not established. Aligned 32-bit bus view explicitly addressed by the cited vendor source. No reset or hardware write effect is established.
  fields as WORD_0470_OPAQUE
0x53DC WORD_53DC_OPAQUE ro — Opaque: meaning not established. Aligned 32-bit bus view explicitly addressed by the cited vendor source. No reset or hardware write effect is established.
  fields as WORD_4E88_OPAQUE
0x544C WORD_544C_OPAQUE ro — Opaque: meaning not established. Aligned 32-bit bus view explicitly addressed by the cited vendor source. No reset or hardware write effect is established.
  fields as WORD_4E7C_OPAQUE
0x5450 WORD_5450_OPAQUE ro — Opaque: meaning not established. Aligned 32-bit bus view explicitly addressed by the cited vendor source. No reset or hardware write effect is established.
  fields as WORD_0470_OPAQUE
0x5458 WORD_5458_OPAQUE ro — Opaque: meaning not established. Aligned 32-bit bus view explicitly addressed by the cited vendor source. No reset or hardware write effect is established.
  fields as WORD_4E88_OPAQUE
0x54C8 WORD_54C8_OPAQUE ro — Opaque: meaning not established. Aligned 32-bit bus view explicitly addressed by the cited vendor source. No reset or hardware write effect is established.
  fields as WORD_4E7C_OPAQUE
0x54CC WORD_54CC_OPAQUE ro — Opaque: meaning not established. Aligned 32-bit bus view explicitly addressed by the cited vendor source. No reset or hardware write effect is established.
  fields as WORD_0470_OPAQUE
0x54D4 WORD_54D4_OPAQUE ro — Opaque: meaning not established. Aligned 32-bit bus view explicitly addressed by the cited vendor source. No reset or hardware write effect is established.
  fields as WORD_4E88_OPAQUE
0x5544 WORD_5544_OPAQUE ro — Opaque: meaning not established. Aligned 32-bit bus view explicitly addressed by the cited vendor source. No reset or hardware write effect is established.
  fields as WORD_4E7C_OPAQUE
0x5548 WORD_5548_OPAQUE ro — Opaque: meaning not established. Aligned 32-bit bus view explicitly addressed by the cited vendor source. No reset or hardware write effect is established.
  fields as WORD_0470_OPAQUE
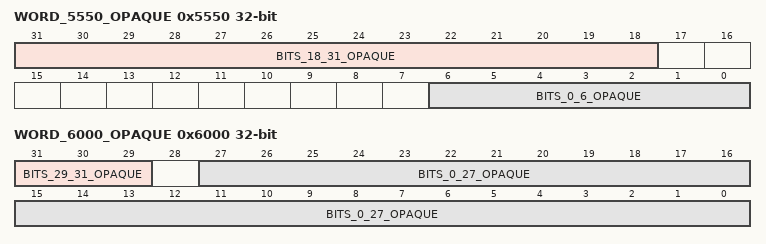
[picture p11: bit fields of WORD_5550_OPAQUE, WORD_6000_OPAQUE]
0x5550 WORD_5550_OPAQUE ro — Opaque: meaning not established. Aligned 32-bit bus view explicitly addressed by the cited vendor source. No reset or hardware write effect is established.
  fields as WORD_4E88_OPAQUE
0x6000 WORD_6000_OPAQUE — Opaque: meaning not established. Aligned 32-bit bus view explicitly addressed by the cited vendor source. No reset or hardware write effect is established.
  [31:29] BITS_29_31_OPAQUE — Opaque: meaning not established. Observed source use; the individual hardware meaning is unknown.
  [27:0] BITS_0_27_OPAQUE — Opaque: meaning not established. Observed source use; the individual hardware meaning is unknown.
0x70DC WORD_70DC_OPAQUE — Opaque: meaning not established. Aligned 32-bit bus view explicitly addressed by the cited vendor source. No reset or hardware write effect is established.
  [16] BIT_16_OPAQUE — Opaque: meaning not established. Observed source use; the individual hardware meaning is unknown.
0x71D4 WORD_71D4_OPAQUE — Opaque: meaning not established. Aligned 32-bit bus view explicitly addressed by the cited vendor source. No reset or hardware write effect is established.
  fields as WORD_0470_OPAQUE
0x7414 WORD_7414_OPAQUE — Opaque: meaning not established. Aligned 32-bit bus view explicitly addressed by the cited vendor source. No reset or hardware write effect is established.
  fields as WORD_0470_OPAQUE
0x7418 WORD_7418_OPAQUE — Opaque: meaning not established. Aligned 32-bit bus view explicitly addressed by the cited vendor source. No reset or hardware write effect is established.
  [20:8] BITS_8_20_OPAQUE — Opaque: meaning not established. Observed source use; the individual hardware meaning is unknown.
0x7C2C WORD_7C2C_OPAQUE — Opaque: meaning not established. Aligned 32-bit bus view explicitly addressed by the cited vendor source. No reset or hardware write effect is established.
  [9:7] BITS_7_9_OPAQUE — Opaque: meaning not established. Observed source use; the individual hardware meaning is unknown.
0x857C WORD_857C_OPAQUE — Opaque: meaning not established. Aligned 32-bit bus view explicitly addressed by the cited vendor source. No reset or hardware write effect is established.
  [17] BIT_17_OPAQUE — Opaque: meaning not established. Observed source use; the individual hardware meaning is unknown.
0x8944 WORD_8944_OPAQUE — Opaque: meaning not established. Aligned 32-bit bus view explicitly addressed by the cited vendor source. No reset or hardware write effect is established.
  [3] BIT_3_OPAQUE — Opaque: meaning not established. Observed source use; the individual hardware meaning is unknown.
0x9830 WORD_9830_OPAQUE — Opaque: meaning not established. Aligned 32-bit bus view explicitly addressed by the cited vendor source. No reset or hardware write effect is established.
  fields as WORD_1018_OPAQUE
0x9834 WORD_9834_OPAQUE ro — Opaque: meaning not established. Aligned 32-bit bus view explicitly addressed by the cited vendor source. No reset or hardware write effect is established.
  fields as WORD_0470_OPAQUE
0x98C0 WORD_98C0_OPAQUE ro — Opaque: meaning not established. Aligned 32-bit bus view explicitly addressed by the cited vendor source. No reset or hardware write effect is established.
  fields as WORD_1018_OPAQUE
